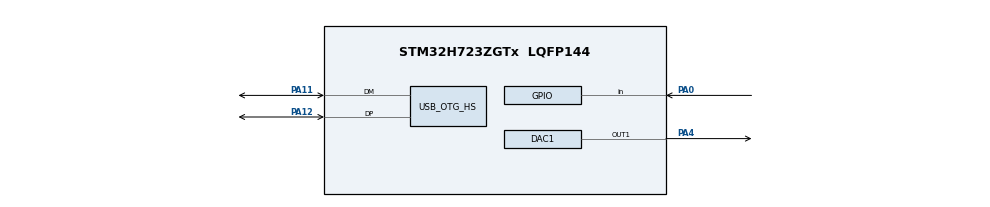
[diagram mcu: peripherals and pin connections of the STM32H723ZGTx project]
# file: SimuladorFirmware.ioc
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CORTEX_M7.default_mode_Activation=1
DAC1.DAC_Channel-DAC_OUT1=DAC_CHANNEL_1
DAC1.DAC_Trigger-DAC_OUT1=DAC_TRIGGER_NONE
Mcu.Family=STM32H7
Mcu.Name=STM32H723ZGTx
Mcu.Package=LQFP144
NVIC.OTG_HS_IRQn=true\:2\:0\:true\:false\:true\:false\:true\:true
NVIC.PriorityGroup=NVIC_PRIORITYGROUP_4
NVIC.TIM1_UP_IRQn=true\:0\:0\:false\:false\:true\:true\:true\:true
NVIC.TIM2_IRQn=true\:1\:0\:true\:false\:true\:true\:true\:true
PA0.GPIO_PuPd=GPIO_PULLDOWN
PA0.Signal=GPIO_Input
PA11.Mode=Device_Only_FS
PA11.Signal=USB_OTG_HS_DM
PA12.Mode=Device_Only_FS
PA12.Signal=USB_OTG_HS_DP
PA13(JTMS/SWDIO).Mode=Serial_Wire
PA13(JTMS/SWDIO).Signal=DEBUG_JTMS-SWDIO
PA14(JTCK/SWCLK).Mode=Serial_Wire
PA14(JTCK/SWCLK).Signal=DEBUG_JTCK-SWCLK
PA4.Signal=COMP_DAC11_group
PH0-OSC_IN.Mode=HSE-External-Oscillator
PH0-OSC_IN.Signal=RCC_OSC_IN
PH1-OSC_OUT.Mode=HSE-External-Oscillator
PH1-OSC_OUT.Signal=RCC_OSC_OUT
ProjectManager.HeapSize=0x200
ProjectManager.StackSize=0x400
ProjectManager.TargetToolchain=CMake
RCC.ADCFreq_Value=129000000
RCC.APB1Freq_Value=137500000
RCC.APB2Freq_Value=137500000
RCC.APB3Freq_Value=137500000
RCC.APB4Freq_Value=137500000
RCC.CortexFreq_Value=550000000
RCC.D1PPRE=RCC_APB3_DIV2
RCC.D2PPRE1=RCC_APB1_DIV2
RCC.D2PPRE2=RCC_APB2_DIV2
RCC.D3PPRE=RCC_APB4_DIV2
RCC.DIVM1=4
RCC.DIVN1=34
RCC.DIVP1=1
RCC.HCLKFreq_Value=275000000
RCC.HPRE=RCC_HCLK_DIV2
RCC.PLL2FRACN=0
RCC.PLL3FRACN=0
RCC.PLLFRACN=3072
RCC.SYSCLKFreq_VALUE=550000000
RCC.SYSCLKSource=RCC_SYSCLKSOURCE_PLLCLK
RCC.USBCLockSelection=RCC_USBCLKSOURCE_HSI48
RCC.USBFreq_Value=48000000
SH.COMP_DAC11_group.0=DAC1_OUT1,DAC_OUT1
TIM2.TIM_MasterOutputTrigger=TIM_TRGO_UPDATE
USB_DEVICE.CLASS_NAME_HS=CDC
USB_DEVICE.VirtualMode=Cdc
USB_DEVICE.VirtualModeHS=Cdc_HS
USB_OTG_HS.VirtualMode-Device_Only_FS=Device_Only_FS
VP_MEMORYMAP_VS_MEMORYMAP.Mode=CurAppReg
VP_TIM1_VS_ClockSourceINT.Mode=Internal
VP_TIM2_VS_ClockSourceINT.Mode=Internal
VP_USB_DEVICE_VS_USB_DEVICE_CDC_HS.Mode=CDC_HS
board=custom

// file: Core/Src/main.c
/* USER CODE BEGIN Header */
/**
  ******************************************************************************
  * @file           : main.c
  * @brief          : Main program body
  ******************************************************************************
  * @attention
  *
  * Copyright (c) 2026 STMicroelectronics.
  * All rights reserved.
  *
  * This software is licensed under terms that can be found in the LICENSE file
  * in the root directory of this software component.
  * If no LICENSE file comes with this software, it is provided AS-IS.
  *
  ******************************************************************************
  */
/* USER CODE END Header */
#include "main.h"
#include "usb_device.h"

/* USER CODE BEGIN Includes */
#include "sm_simulation.h"
#include "usb_comm.h"
/* USER CODE END Includes */

DAC_HandleTypeDef hdac1;

TIM_HandleTypeDef htim1;
TIM_HandleTypeDef htim2;

void SystemClock_Config(void);
static void MPU_Config(void);
static void MX_GPIO_Init(void);
static void MX_DAC1_Init(void);
static void MX_TIM1_Init(void);
static void MX_TIM2_Init(void);

int main(void)
{

  /* MPU Configuration--------------------------------------------------------*/
  MPU_Config();

  /* MCU Configuration--------------------------------------------------------*/

  /* Reset of all peripherals, Initializes the Flash interface and the Systick. */
  HAL_Init();

  /* Configure the system clock */
  SystemClock_Config();

  /* Initialize all configured peripherals */
  MX_GPIO_Init();
  MX_USB_DEVICE_Init();
  MX_DAC1_Init();
  MX_TIM1_Init();
  MX_TIM2_Init();
  /* USER CODE BEGIN 2 */
  USB_Comm_Init();
  SM_Init();
  /* USER CODE END 2 */

  /* Infinite loop */
  while (1)
  {

    /* USER CODE BEGIN 3 */
    SM_Process();
    USB_Comm_ProcessTx();
  }
  /* USER CODE END 3 */
}

void SystemClock_Config(void)
{
  RCC_OscInitTypeDef RCC_OscInitStruct = {0};
  RCC_ClkInitTypeDef RCC_ClkInitStruct = {0};

  /** Supply configuration update enable
  */
  HAL_PWREx_ConfigSupply(PWR_LDO_SUPPLY);

  /** Configure the main internal regulator output voltage
  */
  __HAL_PWR_VOLTAGESCALING_CONFIG(PWR_REGULATOR_VOLTAGE_SCALE0);

  while(!__HAL_PWR_GET_FLAG(PWR_FLAG_VOSRDY)) {}

  /** Initializes the RCC Oscillators according to the specified parameters
  * in the RCC_OscInitTypeDef structure.
  */
  RCC_OscInitStruct.OscillatorType = RCC_OSCILLATORTYPE_HSI48|RCC_OSCILLATORTYPE_HSI;
  RCC_OscInitStruct.HSIState = RCC_HSI_DIV1;
  RCC_OscInitStruct.HSICalibrationValue = 64;
  RCC_OscInitStruct.HSI48State = RCC_HSI48_ON;
  RCC_OscInitStruct.PLL.PLLState = RCC_PLL_ON;
  RCC_OscInitStruct.PLL.PLLSource = RCC_PLLSOURCE_HSI;
  RCC_OscInitStruct.PLL.PLLM = 4;
  RCC_OscInitStruct.PLL.PLLN = 34;
  RCC_OscInitStruct.PLL.PLLP = 1;
  RCC_OscInitStruct.PLL.PLLQ = 2;
  RCC_OscInitStruct.PLL.PLLR = 2;
  RCC_OscInitStruct.PLL.PLLRGE = RCC_PLL1VCIRANGE_3;
  RCC_OscInitStruct.PLL.PLLVCOSEL = RCC_PLL1VCOWIDE;
  RCC_OscInitStruct.PLL.PLLFRACN = 3072;
  if (HAL_RCC_OscConfig(&RCC_OscInitStruct) != HAL_OK)
  {
    Error_Handler();
  }

  /** Initializes the CPU, AHB and APB buses clocks
  */
  RCC_ClkInitStruct.ClockType = RCC_CLOCKTYPE_HCLK|RCC_CLOCKTYPE_SYSCLK
                              |RCC_CLOCKTYPE_PCLK1|RCC_CLOCKTYPE_PCLK2
                              |RCC_CLOCKTYPE_D3PCLK1|RCC_CLOCKTYPE_D1PCLK1;
  RCC_ClkInitStruct.SYSCLKSource = RCC_SYSCLKSOURCE_PLLCLK;
  RCC_ClkInitStruct.SYSCLKDivider = RCC_SYSCLK_DIV1;
  RCC_ClkInitStruct.AHBCLKDivider = RCC_HCLK_DIV2;
  RCC_ClkInitStruct.APB3CLKDivider = RCC_APB3_DIV2;
  RCC_ClkInitStruct.APB1CLKDivider = RCC_APB1_DIV2;
  RCC_ClkInitStruct.APB2CLKDivider = RCC_APB2_DIV2;
  RCC_ClkInitStruct.APB4CLKDivider = RCC_APB4_DIV2;

  if (HAL_RCC_ClockConfig(&RCC_ClkInitStruct, FLASH_LATENCY_3) != HAL_OK)
  {
    Error_Handler();
  }
}

static void MX_DAC1_Init(void)
{

  DAC_ChannelConfTypeDef sConfig = {0};

  /** DAC Initialization
  */
  hdac1.Instance = DAC1;
  if (HAL_DAC_Init(&hdac1) != HAL_OK)
  {
    Error_Handler();
  }

  /** DAC channel OUT1 config
  */
  sConfig.DAC_SampleAndHold = DAC_SAMPLEANDHOLD_DISABLE;
  sConfig.DAC_Trigger = DAC_TRIGGER_NONE;
  sConfig.DAC_OutputBuffer = DAC_OUTPUTBUFFER_ENABLE;
  sConfig.DAC_ConnectOnChipPeripheral = DAC_CHIPCONNECT_DISABLE;
  sConfig.DAC_UserTrimming = DAC_TRIMMING_FACTORY;
  if (HAL_DAC_ConfigChannel(&hdac1, &sConfig, DAC_CHANNEL_1) != HAL_OK)
  {
    Error_Handler();
  }

}

static void MX_TIM1_Init(void)
{

  TIM_ClockConfigTypeDef sClockSourceConfig = {0};
  TIM_MasterConfigTypeDef sMasterConfig = {0};

  htim1.Instance = TIM1;
  htim1.Init.Prescaler = 0;
  htim1.Init.CounterMode = TIM_COUNTERMODE_UP;
  htim1.Init.Period = 65535;
  htim1.Init.ClockDivision = TIM_CLOCKDIVISION_DIV1;
  htim1.Init.RepetitionCounter = 0;
  htim1.Init.AutoReloadPreload = TIM_AUTORELOAD_PRELOAD_DISABLE;
  if (HAL_TIM_Base_Init(&htim1) != HAL_OK)
  {
    Error_Handler();
  }
  sClockSourceConfig.ClockSource = TIM_CLOCKSOURCE_INTERNAL;
  if (HAL_TIM_ConfigClockSource(&htim1, &sClockSourceConfig) != HAL_OK)
  {
    Error_Handler();
  }
  sMasterConfig.MasterOutputTrigger = TIM_TRGO_RESET;
  sMasterConfig.MasterOutputTrigger2 = TIM_TRGO2_RESET;
  sMasterConfig.MasterSlaveMode = TIM_MASTERSLAVEMODE_DISABLE;
  if (HAL_TIMEx_MasterConfigSynchronization(&htim1, &sMasterConfig) != HAL_OK)
  {
    Error_Handler();
  }

}

static void MX_TIM2_Init(void)
{

  TIM_ClockConfigTypeDef sClockSourceConfig = {0};
  TIM_MasterConfigTypeDef sMasterConfig = {0};

  htim2.Instance = TIM2;
  htim2.Init.Prescaler = 0;
  htim2.Init.CounterMode = TIM_COUNTERMODE_UP;
  htim2.Init.Period = 4294967295;
  htim2.Init.ClockDivision = TIM_CLOCKDIVISION_DIV1;
  htim2.Init.AutoReloadPreload = TIM_AUTORELOAD_PRELOAD_DISABLE;
  if (HAL_TIM_Base_Init(&htim2) != HAL_OK)
  {
    Error_Handler();
  }
  sClockSourceConfig.ClockSource = TIM_CLOCKSOURCE_INTERNAL;
  if (HAL_TIM_ConfigClockSource(&htim2, &sClockSourceConfig) != HAL_OK)
  {
    Error_Handler();
  }
  sMasterConfig.MasterOutputTrigger = TIM_TRGO_UPDATE;
  sMasterConfig.MasterSlaveMode = TIM_MASTERSLAVEMODE_DISABLE;
  if (HAL_TIMEx_MasterConfigSynchronization(&htim2, &sMasterConfig) != HAL_OK)
  {
    Error_Handler();
  }

}

static void MX_GPIO_Init(void)
{
  GPIO_InitTypeDef GPIO_InitStruct = {0};

  /* GPIO Ports Clock Enable */
  __HAL_RCC_GPIOH_CLK_ENABLE();
  __HAL_RCC_GPIOA_CLK_ENABLE();

  /*Configure GPIO pin : PA0 */
  GPIO_InitStruct.Pin = GPIO_PIN_0;
  GPIO_InitStruct.Mode = GPIO_MODE_INPUT;
  GPIO_InitStruct.Pull = GPIO_PULLDOWN;
  HAL_GPIO_Init(GPIOA, &GPIO_InitStruct);

}

/* USER CODE BEGIN 4 */
void HAL_TIM_PeriodElapsedCallback(TIM_HandleTypeDef *htim)
{
  if (htim->Instance == TIM1) {
    SM_Timer_MathStep_ISR(); // Roda a f_sim
  }
  else if (htim->Instance == TIM2) {
    SM_Timer_Telemetry_ISR(); // Roda a f_s
  }
}
/* USER CODE END 4 */

 /* MPU Configuration */

void MPU_Config(void)
{
  MPU_Region_InitTypeDef MPU_InitStruct = {0};

  /* Disables the MPU */
  HAL_MPU_Disable();

  /** Initializes and configures the Region and the memory to be protected
  */
  MPU_InitStruct.Enable = MPU_REGION_ENABLE;
  MPU_InitStruct.Number = MPU_REGION_NUMBER0;
  MPU_InitStruct.BaseAddress = 0x0;
  MPU_InitStruct.Size = MPU_REGION_SIZE_4GB;
  MPU_InitStruct.SubRegionDisable = 0x87;
  MPU_InitStruct.TypeExtField = MPU_TEX_LEVEL0;
  MPU_InitStruct.AccessPermission = MPU_REGION_NO_ACCESS;
  MPU_InitStruct.DisableExec = MPU_INSTRUCTION_ACCESS_DISABLE;
  MPU_InitStruct.IsShareable = MPU_ACCESS_SHAREABLE;
  MPU_InitStruct.IsCacheable = MPU_ACCESS_NOT_CACHEABLE;
  MPU_InitStruct.IsBufferable = MPU_ACCESS_NOT_BUFFERABLE;

  HAL_MPU_ConfigRegion(&MPU_InitStruct);
  /* Enables the MPU */
  HAL_MPU_Enable(MPU_PRIVILEGED_DEFAULT);

}

void Error_Handler(void)
{
  __disable_irq();
  while (1)
  {
  }
}
